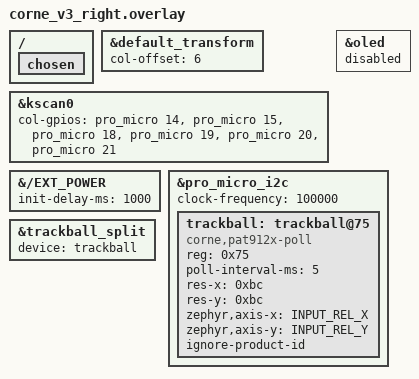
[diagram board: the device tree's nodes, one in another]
/*
 * Copyright (c) 2020 Pete Johanson
 *
 * SPDX-License-Identifier: MIT
 */

#include "corne_v3.dtsi"
#include <input/processors.dtsi>

&default_transform {
	col-offset = <6>;
};

&kscan0 {
	col-gpios
		= <&pro_micro 14 GPIO_ACTIVE_HIGH>
		, <&pro_micro 15 GPIO_ACTIVE_HIGH>
		, <&pro_micro 18 GPIO_ACTIVE_HIGH>
		, <&pro_micro 19 GPIO_ACTIVE_HIGH>
		, <&pro_micro 20 GPIO_ACTIVE_HIGH>
		, <&pro_micro 21 GPIO_ACTIVE_HIGH>
		;
};

&oled {
	status = "disabled";
};

/ {
	chosen {
		/delete-property/ zephyr,display;
	};
};

&{/EXT_POWER} {
	init-delay-ms = <1000>;
};

/*
 * Module: VCC(3.3V), SCL→D3, SDA→D2, MOTION unused (stuck 0 V), GND
 */
&pro_micro_i2c {
	status = "okay";
	clock-frequency = <100000>;

	trackball: trackball@75 {
		compatible = "corne,pat912x-poll";
		reg = <0x75>;
		status = "okay";

		poll-interval-ms = <5>;

		/* Raw register values ≈ 1000 CPI */
		res-x = <0xbc>;
		res-y = <0xbc>;

		zephyr,axis-x = <INPUT_REL_X>;
		zephyr,axis-y = <INPUT_REL_Y>;

		ignore-product-id;
	};
};

&trackball_split {
	device = <&trackball>;
	/* Uncomment / adjust if axes feel wrong for your mount */
	/* input-processors = <&zip_xy_transform INPUT_TRANSFORM_XY_SWAP>; */
};
